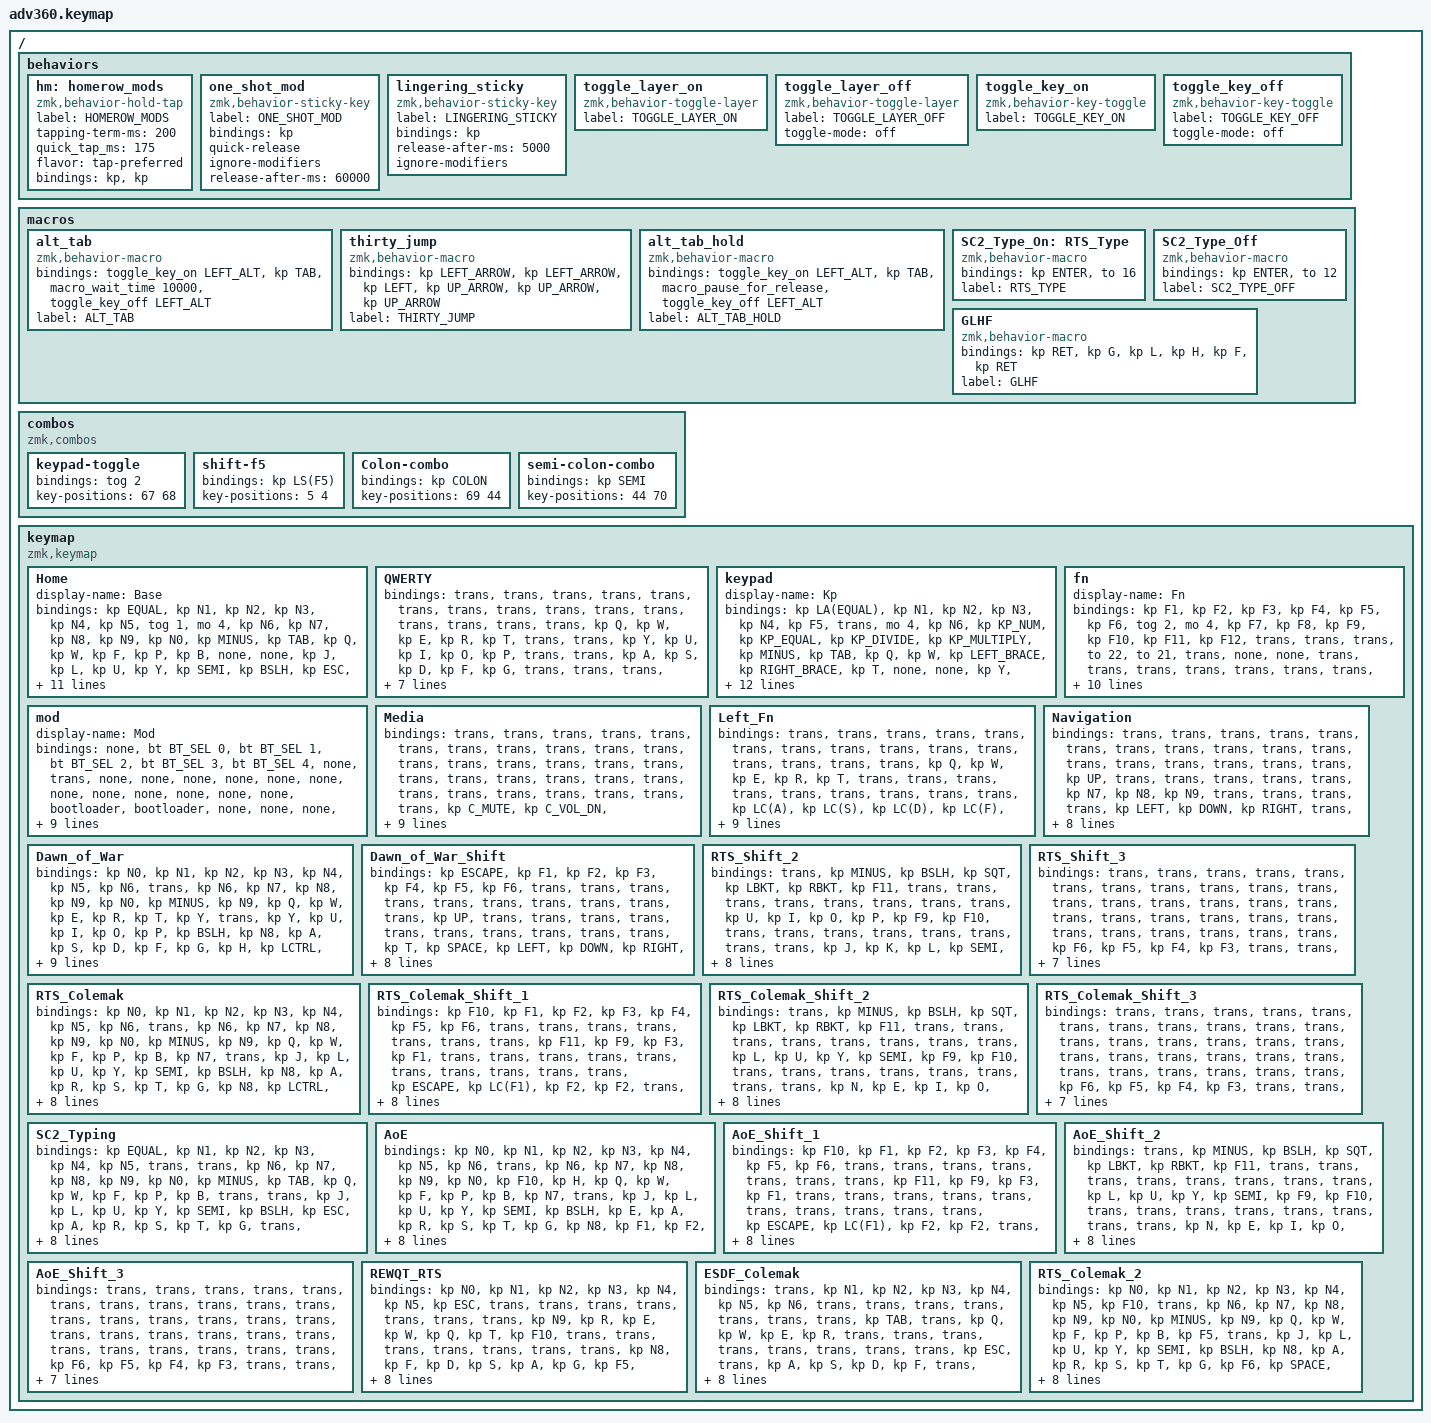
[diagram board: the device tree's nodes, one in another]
#include <dt-bindings/zmk/stp.h>
#include <behaviors.dtsi>
#include <dt-bindings/zmk/backlight.h>
#include <dt-bindings/zmk/bt.h>
#include <dt-bindings/zmk/keys.h>
#include <dt-bindings/zmk/pointing.h>
#include <dt-bindings/zmk/rgb.h>

/ {
    behaviors {
        #include "macros.dtsi"
      #include "version.dtsi"

        hm: homerow_mods {
            compatible = "zmk,behavior-hold-tap";
            label = "HOMEROW_MODS";
            #binding-cells = <2>;
            tapping-term-ms = <200>;
            quick_tap_ms = <175>;
            flavor = "tap-preferred";
            bindings = <&kp>, <&kp>;
        };

        one_shot_mod: one_shot_mod {
            compatible = "zmk,behavior-sticky-key";
            label = "ONE_SHOT_MOD";
            bindings = <&kp>;
            #binding-cells = <1>;
            quick-release;
            ignore-modifiers;
            release-after-ms = <60000>;
        };

        lingering_sticky: lingering_sticky {
            compatible = "zmk,behavior-sticky-key";
            label = "LINGERING_STICKY";
            bindings = <&kp>;
            #binding-cells = <1>;
            release-after-ms = <5000>;
            ignore-modifiers;
        };

        toggle_layer_on: toggle_layer_on {
            compatible = "zmk,behavior-toggle-layer";
            label = "TOGGLE_LAYER_ON";
            #binding-cells = <1>;
        };

        toggle_layer_off: toggle_layer_off {
            compatible = "zmk,behavior-toggle-layer";
            label = "TOGGLE_LAYER_OFF";
            #binding-cells = <1>;
            toggle-mode = "off";
        };

        toggle_key_on: toggle_key_on {
            compatible = "zmk,behavior-key-toggle";
            label = "TOGGLE_KEY_ON";
            #binding-cells = <1>;
        };

        toggle_key_off: toggle_key_off {
            compatible = "zmk,behavior-key-toggle";
            label = "TOGGLE_KEY_OFF";
            #binding-cells = <1>;
            toggle-mode = "off";
        };
    };

    macros {
        alt_tab: alt_tab {
            compatible = "zmk,behavior-macro";
            #binding-cells = <0>;
            bindings =
                <&toggle_key_on LEFT_ALT &kp TAB>,
                <&macro_wait_time 10000>,
                <&toggle_key_off LEFT_ALT>;

            label = "ALT_TAB";
        };

        thirty_jump: thirty_jump {
            compatible = "zmk,behavior-macro";
            #binding-cells = <0>;
            bindings = <&kp LEFT_ARROW &kp LEFT_ARROW &kp LEFT &kp UP_ARROW &kp UP_ARROW &kp UP_ARROW>;
            label = "THIRTY_JUMP";
        };

        alt_tab_hold: alt_tab_hold {
            compatible = "zmk,behavior-macro";
            #binding-cells = <0>;
            bindings =
                <&toggle_key_on LEFT_ALT &kp TAB>,
                <&macro_pause_for_release>,
                <&toggle_key_off LEFT_ALT>;

            label = "ALT_TAB_HOLD";
        };

        SC2_Type_On: RTS_Type {
            compatible = "zmk,behavior-macro";
            #binding-cells = <0>;
            bindings = <&kp ENTER &to 16>;
            label = "RTS_TYPE";
        };

        SC2_Type_Off: SC2_Type_Off {
            compatible = "zmk,behavior-macro";
            #binding-cells = <0>;
            bindings = <&kp ENTER &to 12>;
            label = "SC2_TYPE_OFF";
        };

        GLHF: GLHF {
            compatible = "zmk,behavior-macro";
            #binding-cells = <0>;
            bindings = <&kp RET &kp G &kp L &kp H &kp F &kp RET>;
            label = "GLHF";
        };
    };

    combos {
        compatible = "zmk,combos";

        keypad-toggle {
            bindings = <&tog 2>;
            key-positions = <67 68>;
        };

        shift-f5 {
            bindings = <&kp LS(F5)>;
            key-positions = <5 4>;
        };

        Colon-combo {
            bindings = <&kp COLON>;
            key-positions = <69 44>;
        };

        semi-colon-combo {
            bindings = <&kp SEMI>;
            key-positions = <44 70>;
        };
    };

    keymap {
        compatible = "zmk,keymap";

        Home {
            display-name = "Base";
            bindings = <
&kp EQUAL  &kp N1     &kp N2    &kp N3    &kp N4     &kp N5  &tog 1                                                                                        &mo 4        &kp N6  &kp N7  &kp N8     &kp N9    &kp N0    &kp MINUS
&kp TAB    &kp Q      &kp W     &kp F     &kp P      &kp B   &none                                                                                         &none        &kp J   &kp L   &kp U      &kp Y     &kp SEMI  &kp BSLH
&kp ESC    &kp A      &kp R     &kp S     &kp T      &kp G   &none            &kp LCTRL  &kp LALT                 &kp LGUI      &kp RCTRL                  &none        &kp M   &kp N   &kp E      &kp I     &kp O     &kp SQT
&kp BSPC   &kp Z      &kp X     &kp C     &kp D      &kp V                               &lt 5 LC(BACKSPACE)      &kp PG_UP                                             &kp K   &kp H   &kp COMMA  &kp DOT   &kp FSLH  &kp RET
&mo 6      &kp GRAVE  &kp CAPS  &kp LEFT  &kp RIGHT          &lt 7 BACKSPACE  &kp SPACE  &lt 2 DEL                &lt 2 DOLLAR  &one_shot_mod RIGHT_SHIFT  &lt 2 ENTER          &kp UP  &kp DOWN   &kp LBKT  &kp RBKT  &mo 3
            >;
        };

        QWERTY {
            bindings = <
&trans  &trans  &trans  &trans  &trans  &trans  &trans                                      &trans  &trans  &trans  &trans     &trans   &trans    &trans
&trans  &kp Q   &kp W   &kp E   &kp R   &kp T   &trans                                      &trans  &kp Y   &kp U   &kp I      &kp O    &kp P     &trans
&trans  &kp A   &kp S   &kp D   &kp F   &kp G   &trans  &trans  &trans      &trans  &trans  &trans  &kp H   &kp J   &kp K      &kp L    &kp SEMI  &trans
&trans  &kp Z   &kp X   &kp C   &kp V   &kp B                   &trans      &trans                  &kp N   &kp M   &kp COMMA  &kp DOT  &kp FSLH  &trans
&trans  &trans  &trans  &trans  &trans          &trans  &trans  &trans      &trans  &trans  &trans          &trans  &trans     &trans   &trans    &trans
            >;
        };

        keypad {
            display-name = "Kp";
            bindings = <
&kp LA(EQUAL)  &kp N1     &kp N2    &kp N3                &kp N4                 &kp F5  &trans                                                   &mo 4      &kp N6  &kp KP_NUM  &kp KP_EQUAL  &kp KP_DIVIDE  &kp KP_MULTIPLY  &kp MINUS
&kp TAB        &kp Q      &kp W     &kp LEFT_BRACE        &kp RIGHT_BRACE        &kp T   &none                                                    &none      &kp Y   &kp N7      &kp N8        &kp N9         &kp MINUS        &kp BSLH
&kp ESC        &kp LBKT   &kp RBKT  &kp LEFT_PARENTHESIS  &kp RIGHT_PARENTHESIS  &kp G   &none     &kp LCTRL  &kp LALT      &kp LGUI   &kp RCTRL  &none      &kp H   &kp N4      &kp N5        &kp N6         &kp PLUS         &kp SQT
&kp ESC        &kp Z      &kp X     &kp LBKT              &kp RBKT               &kp B                        &kp HOME      &kp PG_UP                        &kp N0  &kp N1      &kp N2        &kp N3         &kp RET          &kp RSHFT
&mo 3          &kp GRAVE  &kp CAPS  &kp LEFT              &kp RIGHT                      &kp BSPC  &kp DEL    &kp END       &kp PG_DN  &kp ENTER  &kp KP_N0          &kp N0      &kp DOWN      &kp DOT        &kp RBKT         &mo 3
            >;
        };

        fn {
            display-name = "Fn";
            bindings = <
&kp F1  &kp F2  &kp F3              &kp F4               &kp F5               &kp F6  &tog 2                                        &mo 4   &kp F7  &kp F8  &kp F9  &kp F10  &kp F11  &kp F12
&trans  &trans  &trans              &to 22               &to 21               &trans  &none                                         &none   &trans  &trans  &trans  &trans   &trans   &trans
&trans  &trans  &toggle_layer_on 8  &toggle_layer_on 12  &toggle_layer_on 17  &trans  &none     &trans  &trans      &trans  &trans  &none   &trans  &trans  &trans  &kp INS  &trans   &trans
&trans  &trans  &trans              &to 23               &trans               &trans                    &trans      &trans                  &trans  &trans  &trans  &trans   &trans   &trans
&trans  &trans  &trans              &trans               &trans                       &alt_tab  &trans  &trans      &trans  &trans  &trans          &trans  &trans  &trans   &trans   &trans
            >;
        };

        mod {
            display-name = "Mod";
            bindings = <
&none           &bt BT_SEL 0  &bt BT_SEL 1  &bt BT_SEL 2  &bt BT_SEL 3  &bt BT_SEL 4  &none                                                  &trans           &none  &none       &none       &none  &none  &none
&none           &none         &none         &none         &none         &none         &bootloader                                            &bootloader      &none  &none       &none       &none  &none  &none
&studio_unlock  &none         &none         &none         &none         &none         &none        &none  &none      &bt BT_CLR  &none       &stp STP_BAT     &none  &none       &none       &none  &none  &none
&none           &none         &none         &none         &macro_ver    &none                             &none      &none                                    &none  &none       &none       &none  &none  &none
&none           &none         &none         &none         &none                       &none        &none  &none      &none       &bl BL_TOG  &rgb_ug RGB_TOG         &bl BL_INC  &bl BL_DEC  &none  &none  &none
            >;
        };

        Media {
            bindings = <
&trans  &trans  &trans          &trans        &trans            &trans  &trans                                      &trans  &trans  &trans  &trans  &trans  &trans  &trans
&trans  &trans  &trans          &trans        &trans            &trans  &trans                                      &trans  &trans  &trans  &trans  &trans  &trans  &trans
&trans  &trans  &kp C_MUTE      &kp C_VOL_DN  &kp C_VOLUME_UP   &trans  &trans  &trans  &trans      &trans  &trans  &trans  &trans  &trans  &trans  &trans  &trans  &trans
&trans  &trans  &kp C_PREVIOUS  &kp C_NEXT    &kp C_PLAY_PAUSE  &trans                  &trans      &trans                  &trans  &trans  &trans  &trans  &trans  &trans
&trans  &trans  &trans          &trans        &trans                    &trans  &trans  &trans      &trans  &trans  &trans          &trans  &trans  &trans  &trans  &trans
            >;
        };

        Left_Fn {
            bindings = <
&trans  &trans          &trans     &trans       &trans     &trans     &trans                                                    &trans  &trans  &trans  &trans  &trans  &trans  &trans
&trans  &kp Q           &kp W      &kp E        &kp R      &kp T      &trans                                                    &trans  &trans  &trans  &trans  &trans  &trans  &trans
&trans  &kp LC(A)       &kp LC(S)  &kp LC(D)    &kp LC(F)  &kp G      &thirty_jump   &trans       &trans        &trans  &trans  &trans  &trans  &to 8   &trans  &trans  &trans  &trans
&trans  &kp LC(Z)       &kp LC(X)  &kp LC(C)    &kp LC(V)  &kp LC(B)                              &trans        &trans                  &trans  &trans  &trans  &trans  &trans  &trans
&trans  &kp LEFT_SHIFT  &trans     &kp LS(TAB)  &kp TAB               &alt_tab_hold  &kp LC(TAB)  &alt_tab      &trans  &trans  &trans          &trans  &trans  &trans  &trans  &trans
            >;
        };

        Navigation {
            bindings = <
&trans  &trans  &trans    &trans        &trans          &trans  &trans                                      &trans  &trans  &trans  &trans  &trans  &trans  &trans
&trans  &trans  &trans    &kp UP        &trans          &trans  &trans                                      &trans  &trans  &kp N7  &kp N8  &kp N9  &trans  &trans
&trans  &trans  &kp LEFT  &kp DOWN      &kp RIGHT       &trans  &trans  &trans  &trans      &trans  &trans  &trans  &trans  &kp N4  &kp N5  &kp N6  &trans  &trans
&trans  &trans  &trans    &msc SCRL_UP  &msc SCRL_DOWN  &trans                  &trans      &trans                  &trans  &kp N1  &kp N2  &kp N3  &trans  &trans
&trans  &trans  &trans    &kp PAGE_UP   &kp PAGE_DOWN           &trans  &trans  &trans      &trans  &trans  &kp N0          &trans  &trans  &trans  &trans  &trans
            >;
        };

        Dawn_of_War {
            bindings = <
&kp N0        &kp N1     &kp N2    &kp N3     &kp N4     &kp N5  &kp N6                                                              &trans     &kp N6  &kp N7  &kp N8     &kp N9    &kp N0    &kp MINUS
&kp N9        &kp Q      &kp W     &kp E      &kp R      &kp T   &kp Y                                                               &trans     &kp Y   &kp U   &kp I      &kp O     &kp P     &kp BSLH
&kp N8        &kp A      &kp S     &kp D      &kp F      &kp G   &kp H    &kp LCTRL       &kp LEFT_ALT      &trans  &trans           &trans     &kp H   &kp J   &kp K      &kp L     &kp SEMI  &kp SQT
&kp N7        &kp Z      &kp X     &kp C      &kp V      &kp B                            &kp SPACE         &trans                              &kp N   &kp M   &kp COMMA  &kp DOT   &kp FSLH  &kp RET
&kp NUMBER_6  &kp LC(P)  &kp LEFT  &kp RIGHT  &kp GRAVE          &kp TAB  &kp LEFT_SHIFT  &mo 9             &trans  &kp RIGHT_SHIFT  &kp ENTER          &kp UP  &kp DOWN   &kp LBKT  &kp RBKT  &to 0
            >;
        };

        Dawn_of_War_Shift {
            bindings = <
&kp ESCAPE     &kp F1      &kp F2      &kp F3      &kp F4      &kp F5      &kp F6                                      &trans  &trans  &trans  &trans  &trans  &trans  &trans
&trans         &trans      &trans      &kp UP      &trans      &trans      &trans                                      &trans  &trans  &trans  &trans  &trans  &trans  &trans
&kp T          &kp SPACE   &kp LEFT    &kp DOWN    &kp RIGHT   &trans      &trans  &trans  &trans      &trans  &trans  &trans  &trans  &trans  &trans  &trans  &trans  &trans
&kp LC(SPACE)  &kp LC(F1)  &kp LC(F2)  &kp LC(F3)  &kp LC(F4)  &kp LC(F5)                  &trans      &trans                  &trans  &trans  &trans  &trans  &trans  &trans
&kp LC(R)      &trans      &trans      &trans      &trans                  &trans  &trans  &trans      &trans  &trans  &trans          &trans  &trans  &trans  &trans  &trans
            >;
        };

        RTS_Shift_2 {
            bindings = <
&trans  &kp MINUS  &kp BSLH   &kp SQT  &kp LBKT  &kp RBKT  &kp F11                                              &trans  &trans  &trans  &trans  &trans  &trans  &trans
&trans  &kp U      &kp I      &kp O    &kp P     &kp F9    &kp F10                                              &trans  &trans  &trans  &trans  &trans  &trans  &trans
&trans  &kp J      &kp K      &kp L    &kp SEMI  &kp SQT   &trans   &kp LCTRL       &trans      &trans  &trans  &trans  &trans  &trans  &trans  &trans  &trans  &trans
&trans  &kp M      &kp COMMA  &kp DOT  &kp FSLH  &kp FSLH                           &trans      &trans                  &trans  &trans  &trans  &trans  &trans  &trans
&trans  &trans     &trans     &trans   &trans              &trans   &kp LEFT_SHIFT  &trans      &trans  &trans  &trans          &trans  &trans  &trans  &trans  &trans
            >;
        };

        RTS_Shift_3 {
            bindings = <
&trans  &trans  &trans  &trans  &trans  &trans  &trans                                      &trans  &trans  &trans  &trans  &trans  &trans  &trans
&trans  &trans  &trans  &trans  &trans  &trans  &trans                                      &trans  &trans  &trans  &trans  &trans  &trans  &trans
&trans  &kp F6  &kp F5  &kp F4  &kp F3  &trans  &trans  &trans  &trans      &trans  &trans  &trans  &trans  &trans  &trans  &trans  &trans  &trans
&trans  &trans  &trans  &kp F8  &kp F7  &trans                  &trans      &trans                  &trans  &trans  &trans  &trans  &trans  &trans
&trans  &trans  &trans  &trans  &trans          &trans  &trans  &trans      &trans  &trans  &trans          &trans  &trans  &trans  &trans  &trans
            >;
        };

        RTS_Colemak {
            bindings = <
&kp N0  &kp N1    &kp N2     &kp N3      &kp N4     &kp N5  &kp N6                                                        &trans        &kp N6  &kp N7  &kp N8     &kp N9    &kp N0    &kp MINUS
&kp N9  &kp Q     &kp W      &kp F       &kp P      &kp B   &kp N7                                                        &trans        &kp J   &kp L   &kp U      &kp Y     &kp SEMI  &kp BSLH
&kp N8  &kp A     &kp R      &kp S       &kp T      &kp G   &kp N8   &kp LCTRL       &kp LEFT_ALT      &trans  &trans     &trans        &kp M   &GLHF   &kp E      &kp I     &kp O     &kp SQT
&kp N7  &kp Z     &kp X      &kp C       &kp D      &kp V                            &mo 14            &trans                           &kp K   &kp H   &kp COMMA  &kp DOT   &kp FSLH  &kp BSPC
&kp N6  &mkp MB3  &kp COMMA  &kp PERIOD  &kp GRAVE          &kp TAB  &kp LEFT_SHIFT  &mo 13            &trans  &kp SPACE  &SC2_Type_On          &kp UP  &kp DOWN   &kp LBKT  &kp RBKT  &to 0
            >;
        };

        RTS_Colemak_Shift_1 {
            bindings = <
&kp F10       &kp F1      &kp F2     &kp F3     &kp F4     &kp F5    &kp F6                                      &trans  &trans  &trans  &trans  &trans  &trans  &trans
&kp F11       &kp F9      &kp F3     &kp F1     &trans     &trans    &trans                                      &trans  &trans  &trans  &trans  &trans  &trans  &trans
&kp ESCAPE    &kp LC(F1)  &kp F2     &kp F2     &trans     &kp BSPC  &trans  &trans  &trans      &trans  &trans  &trans  &trans  &trans  &trans  &trans  &trans  &trans
&kp LCTRL     &kp LC(Z)   &kp LC(X)  &kp LC(C)  &kp LC(V)  &kp F12                   &trans      &trans                  &trans  &trans  &trans  &trans  &trans  &trans
&kp LEFT_ALT  &trans      &trans     &trans     &trans               &trans  &trans  &trans      &trans  &trans  &trans          &trans  &trans  &trans  &trans  &trans
            >;
        };

        RTS_Colemak_Shift_2 {
            bindings = <
&trans  &kp MINUS  &kp BSLH   &kp SQT  &kp LBKT  &kp RBKT  &kp F11                                              &trans  &trans  &trans  &trans  &trans  &trans  &trans
&trans  &kp L      &kp U      &kp Y    &kp SEMI  &kp F9    &kp F10                                              &trans  &trans  &trans  &trans  &trans  &trans  &trans
&trans  &kp N      &kp E      &kp I    &kp O     &kp BSPC  &trans   &kp LCTRL       &trans      &trans  &trans  &trans  &trans  &trans  &trans  &trans  &trans  &trans
&trans  &kp H      &kp COMMA  &kp DOT  &kp FSLH  &kp RBKT                           &trans      &trans                  &trans  &trans  &trans  &trans  &trans  &trans
&trans  &trans     &trans     &trans   &trans              &trans   &kp LEFT_SHIFT  &trans      &trans  &trans  &trans          &trans  &trans  &trans  &trans  &trans
            >;
        };

        RTS_Colemak_Shift_3 {
            bindings = <
&trans  &trans  &trans  &trans  &trans  &trans  &trans                                      &trans  &trans  &trans  &trans  &trans  &trans  &trans
&trans  &trans  &trans  &trans  &trans  &trans  &trans                                      &trans  &trans  &trans  &trans  &trans  &trans  &trans
&trans  &kp F6  &kp F5  &kp F4  &kp F3  &trans  &trans  &trans  &trans      &trans  &trans  &trans  &trans  &trans  &trans  &trans  &trans  &trans
&trans  &trans  &trans  &kp F8  &kp F7  &trans                  &trans      &trans                  &trans  &trans  &trans  &trans  &trans  &trans
&trans  &trans  &trans  &trans  &trans          &trans  &trans  &trans      &trans  &trans  &trans          &trans  &trans  &trans  &trans  &trans
            >;
        };

        SC2_Typing {
            bindings = <
&kp EQUAL  &kp N1  &kp N2  &kp N3  &kp N4  &kp N5  &trans                                                          &trans         &kp N6  &kp N7  &kp N8     &kp N9   &kp N0    &kp MINUS
&kp TAB    &kp Q   &kp W   &kp F   &kp P   &kp B   &trans                                                          &trans         &kp J   &kp L   &kp U      &kp Y    &kp SEMI  &kp BSLH
&kp ESC    &kp A   &kp R   &kp S   &kp T   &kp G   &trans    &kp LCTRL  &kp LALT          &kp LGUI      &kp RCTRL  &trans         &kp M   &kp N   &kp E      &kp I    &kp O     &kp SQT
&kp BSPC   &kp Z   &kp X   &kp C   &kp D   &kp V                        &kp LC(BSPC)      &kp BSPC                                &kp K   &kp H   &kp COMMA  &kp DOT  &kp FSLH  &kp RET
&trans     &trans  &trans  &trans  &trans          &kp BSPC  &kp SPACE  &kp DEL           &kp LS(DLLR)  &kp LSHFT  &SC2_Type_Off          &trans  &trans     &trans   &trans    &trans
            >;
        };

        AoE {
            bindings = <
&kp N0  &kp N1   &kp N2     &kp N3      &kp N4     &kp N5  &kp N6                                                                  &trans   &kp N6  &kp N7  &kp N8     &kp N9    &kp N0    &kp F10
&kp H   &kp Q    &kp W      &kp F       &kp P      &kp B   &kp N7                                                                  &trans   &kp J   &kp L   &kp U      &kp Y     &kp SEMI  &kp BSLH
&kp E   &kp A    &kp R      &kp S       &kp T      &kp G   &kp N8             &kp F1          &kp F2            &trans  &trans     &trans   &kp M   &kp N   &kp E      &kp I     &kp O     &kp SQT
&kp U   &kp Z    &kp X      &kp C       &kp D      &kp V                                      &kp LEFT_ALT      &trans                      &kp K   &kp H   &kp COMMA  &kp DOT   &kp FSLH  &kp BSPC
&kp N9  &kp SQT  &kp COMMA  &kp PERIOD  &kp GRAVE          &kp LS(LA(LCTRL))  &kp LEFT_SHIFT  &kp LCTRL         &trans  &kp SPACE  &kp RET          &kp UP  &kp DOWN   &kp LBKT  &kp RBKT  &to 0
            >;
        };

        AoE_Shift_1 {
            bindings = <
&kp F10       &kp F1      &kp F2     &kp F3     &kp F4     &kp F5    &kp F6                                      &trans  &trans  &trans  &trans  &trans  &trans  &trans
&kp F11       &kp F9      &kp F3     &kp F1     &trans     &trans    &trans                                      &trans  &trans  &trans  &trans  &trans  &trans  &trans
&kp ESCAPE    &kp LC(F1)  &kp F2     &kp F2     &trans     &kp BSPC  &trans  &trans  &trans      &trans  &trans  &trans  &trans  &trans  &trans  &trans  &trans  &trans
&kp LCTRL     &kp LC(Z)   &kp LC(X)  &kp LC(C)  &kp LC(V)  &kp F12                   &trans      &trans                  &trans  &trans  &trans  &trans  &trans  &trans
&kp LEFT_ALT  &trans      &trans     &trans     &trans               &trans  &trans  &trans      &trans  &trans  &trans          &trans  &trans  &trans  &trans  &trans
            >;
        };

        AoE_Shift_2 {
            bindings = <
&trans  &kp MINUS  &kp BSLH   &kp SQT  &kp LBKT  &kp RBKT  &kp F11                                              &trans  &trans  &trans  &trans  &trans  &trans  &trans
&trans  &kp L      &kp U      &kp Y    &kp SEMI  &kp F9    &kp F10                                              &trans  &trans  &trans  &trans  &trans  &trans  &trans
&trans  &kp N      &kp E      &kp I    &kp O     &kp BSPC  &trans   &kp LCTRL       &trans      &trans  &trans  &trans  &trans  &trans  &trans  &trans  &trans  &trans
&trans  &kp H      &kp COMMA  &kp DOT  &kp FSLH  &kp RBKT                           &trans      &trans                  &trans  &trans  &trans  &trans  &trans  &trans
&trans  &trans     &trans     &trans   &trans              &trans   &kp LEFT_SHIFT  &trans      &trans  &trans  &trans          &trans  &trans  &trans  &trans  &trans
            >;
        };

        AoE_Shift_3 {
            bindings = <
&trans  &trans  &trans  &trans  &trans  &trans  &trans                                      &trans  &trans  &trans  &trans  &trans  &trans  &trans
&trans  &trans  &trans  &trans  &trans  &trans  &trans                                      &trans  &trans  &trans  &trans  &trans  &trans  &trans
&trans  &kp F6  &kp F5  &kp F4  &kp F3  &trans  &trans  &trans  &trans      &trans  &trans  &trans  &trans  &trans  &trans  &trans  &trans  &trans
&trans  &trans  &trans  &kp F8  &kp F7  &trans                  &trans      &trans                  &trans  &trans  &trans  &trans  &trans  &trans
&trans  &trans  &trans  &trans  &trans          &trans  &trans  &trans      &trans  &trans  &trans          &trans  &trans  &trans  &trans  &trans
            >;
        };

        REWQT_RTS {
            bindings = <
&kp N0  &kp N1  &kp N2  &kp N3  &kp N4  &kp N5  &kp ESC                                            &trans  &trans  &trans  &trans  &trans  &trans  &trans
&kp N9  &kp R   &kp E   &kp W   &kp Q   &kp T   &kp F10                                            &trans  &trans  &trans  &trans  &trans  &trans  &trans
&kp N8  &kp F   &kp D   &kp S   &kp A   &kp G   &kp F5   &kp SPACE  &kp BSPC       &trans  &trans  &trans  &trans  &trans  &trans  &trans  &trans  &trans
&kp N7  &kp V   &kp C   &kp X   &kp Z   &kp B                       &kp LALT       &trans                  &trans  &trans  &trans  &trans  &trans  &trans
&kp N6  &kp F1  &kp F2  &kp F3  &kp F4          &kp TAB  &kp LSHFT  &kp LCTRL      &trans  &trans  &trans          &trans  &trans  &trans  &trans  &to 0
            >;
        };

        ESDF_Colemak {
            bindings = <
&trans     &kp N1  &kp N2  &kp N3  &kp N4  &kp N5  &kp N6                                             &trans  &trans  &trans  &trans  &trans  &trans  &trans
&kp TAB    &trans  &kp Q   &kp W   &kp E   &kp R   &trans                                             &trans  &trans  &trans  &trans  &trans  &trans  &trans
&kp ESC    &trans  &kp A   &kp S   &kp D   &kp F   &trans    &kp LCTRL  &kp LALT      &trans  &trans  &trans  &trans  &trans  &trans  &trans  &trans  &trans
&kp LSHFT  &trans  &kp Z   &kp X   &kp C   &kp V                        &mo 5         &trans                  &trans  &trans  &trans  &trans  &trans  &trans
&trans     &trans  &trans  &trans  &trans          &kp BSPC  &kp SPACE  &trans        &trans  &trans  &trans          &trans  &trans  &trans  &trans  &to 0
            >;
        };

        RTS_Colemak_2 {
            bindings = <
&kp N0  &kp N1  &kp N2  &kp N3  &kp N4  &kp N5  &kp F10                                                        &trans        &kp N6  &kp N7  &kp N8     &kp N9    &kp N0    &kp MINUS
&kp N9  &kp Q   &kp W   &kp F   &kp P   &kp B   &kp F5                                                         &trans        &kp J   &kp L   &kp U      &kp Y     &kp SEMI  &kp BSLH
&kp N8  &kp A   &kp R   &kp S   &kp T   &kp G   &kp F6   &kp SPACE       &kp BACKSPACE      &trans  &trans     &trans        &kp M   &GLHF   &kp E      &kp I     &kp O     &kp SQT
&kp N7  &kp Z   &kp X   &kp C   &kp D   &kp V                            &kp LEFT_ALT       &trans                           &kp K   &kp H   &kp COMMA  &kp DOT   &kp FSLH  &kp BSPC
&kp N6  &kp F1  &kp F2  &kp F3  &kp F4          &kp TAB  &kp LEFT_SHIFT  &kp LCTRL          &trans  &kp SPACE  &SC2_Type_On          &kp UP  &kp DOWN   &kp LBKT  &kp RBKT  &to 0
            >;
        };
    };
};
